# alb32r003x register map
Vendor: ALB; Series: ALB RT SoC
CPU: ALB XF, little endian
Registers are 32-bit, access not given, reset 0x0 unless marked. A register's access mark holds for its fields unless they carry their own. Offsets are from the block's base; [hi:lo] are bit positions.

## LIN1 — LIN1: Local Interconnect Network controller 1 for single-wire automotive serial communication
Base 0x27000000
Same registers: LIN2 0x27001000
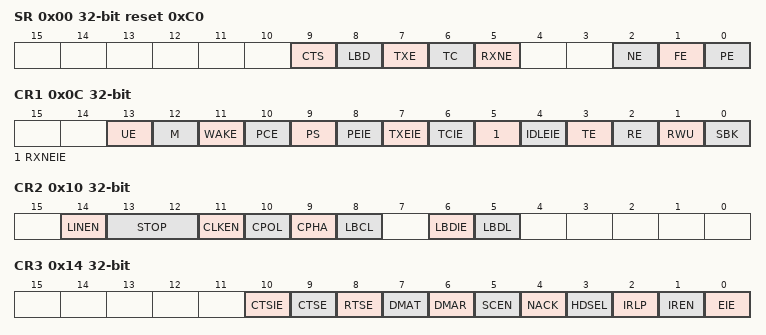
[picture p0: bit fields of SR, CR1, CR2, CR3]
0x00 SR access per field reset 0xC0 — USART status register. Monitors the status of the USART communication interface.
  [9] CTS rw — CTS Flag:This bit is set by hardware when the nCTS input changes state
    0=No change on nCTS status line; 1=Change on nCTS status line
  [8] LBD rw — LIN Break Detection Flag
    0=No LIN break (LIN break not detected); 1=LIN break detected
  [7] TXE ro — Transmit Data Register Empty
    0=Nottransferred (Data not transferred to shift register); 1=Transferred (Data transferred to shift register)
  [6] TC rw — Transmission Complete
    0=Incomplete (Transmission not complete); 1=Complete (Transmission complete)
  [5] RXNE rw — Read Data Register Not Empty
    0=Noreceived (No data received); 1=Received data ready to be read
  [2] NE ro — Noise Error Flag
    0=No noise detected; 1=Noise detected
  [1] FE ro — Framing Error
    0=Noerror (No framing error detected); 1=Error (Framing error or break character detected)
  [0] PE ro — Parity Error
    0=No parity error; 1=Parity error
0x04 DR — USART data register. A bidirectional register for transmitting and receiving data.
0x08 BRR — USART baud rate register. Used to set the baud rate for communication.
0x0C CR1 rw — USART control register 1. Contains the main configuration bits and enable bits.
  [13] UE — USART enable or disabled
    0=Disabled (USART prescaler and output disabled); 1=Enabled (USART module enabled)
  [12] M — Word length:This bit defines the data word length. It is set and cleared by software.
    0=1 Start bit, 8 data bits, n stop bits; 1=1 Start bit, 9 data bits, n stop bits
  [11] WAKE — Wakeup method:This bit determines the USART wakeup method. It is set and cleared by software.
    0=Wake up by idle bus; 1=Wake up by address mark
  [10] PCE — Parity control enable or disable
    0=Disabled (Parity control disabled); 1=Enabled (Parity control enabled)
  [9] PS — Parity selection
    0=Even parity; 1=Odd parity
  [8] PEIE — PE interrupt enable or disable
    0=Disabled (Interrupt generation disabled); 1=Enabled (A USART interrupt is generated when PE=1 in USART_SR)
  [7] TXEIE — TXE interrupt enable or disable
    0=Disabled (Interrupt generation disabled); 1=Enabled (A USART interrupt is generated when TXE=1 in USART_SR)
  [6] TCIE — Transmission complete interrupt enable or disable
    0=Disabled (Interrupt generation disabled); 1=Enabled (A USART interrupt is generated when TC=1 in USART_SR)
  [5] RXNEIE — RXNE interrupt enable or disable
    0=Disabled (Interrupt generation disabled); 1=Enabled (A USART interrupt is generated when ORE=1 or RXNE=1 in USART_SR)
  [4] IDLEIE — IDLE interrupt enable or disbale
    0=Disabled (Interrupt generation disabled); 1=Enabled (A USART interrupt is generated when IDLE=1 in USART_SR)
  [3] TE — Transmitter enable or disbale
    0=Disabled (Transmitter disabled); 1=Enabled (Transmitter enabled)
  [2] RE — Receiver enable or disbale
    0=Disabled (Receiver disabled); 1=Enabled (Receiver enabled, begins searching for start bits on the RX pin)
  [1] RWU — Receiver wakeup:This bit determines whether the USART is put into mute mode.
    0=Operation mode (Receiver in normal operation mode); 1=Mute mode (Receiver in mute mode)
  [0] SBK — Send break:This bit is used to send a break character.
    0=Notbreak (No break character to be sent); 1=Break character will be sent
0x10 CR2 rw — USART control register 2. Configures additional features such as stop bits and clock output.
  [14] LINEN — LIN mode enable or disable
    0=Disabled (LIN mode disabled); 1=Enabled (LIN mode enabled)
  [13:12] STOP — STOP bits:These 2 bits set the number of stop bits.
    0=1 stop bit; 1=0.5 stop bits; 2=2 stop bits; 3=1.5 stop bits
  [11] CLKEN — Clock enable or disable
    0=Disabled (CK pin disabled); 1=Enabled (CK pin enabled)
  [10] CPOL — Clock polarity
    0=low (CK pin remains low during bus idle); 1=high (CK pin remains high during bus idle)
  [9] CPHA — Clock phase
    0=on the second clock edge (Data capture on the first clock edge); 1=on the second clock edge (Data capture on the second clock edge)
  [8] LBCL — Last bit clock pulse
    0=not output (Clock pulse for the last data bit is not output on CK); 1=output (Clock pulse for the last data bit is output on CK)
  [6] LBDIE — LIN break detection interrupt enable or disable
    0=Disabled (Interrupt disabled); 1=Enabled (An interrupt is generated whenever LBD=1 in the USART_SR register.)
  [5] LBDL — LIN break detection length
    0=10-bit break detection; 1=11-bit break detection
0x14 CR3 rw — USART control register 3. Configures advanced features like DMA and hardware flow control.
  [10] CTSIE — CTS interrupt enable or disable
    0=Disabled (Interrupt disabled); 1=Enabled (An interrupt is generated when CTS=1 in the USART_SR register.)
  [9] CTSE — CTS enable or disable
    0=Disabled (CTS hardware flow control disabled); 1=Enabled (CTS mode enabled)
  [8] RTSE — RTS enable or disable
    0=Disabled (RTS hardware flow control disabled); 1=Enabled (RTS mode enabled)
  [7] DMAT — DMA enable transmitter
    0=Disabled (DMA mode for transmission disabled); 1=Enabled (DMA mode for transmission enabled)
  [6] DMAR — DMA enable receiver
    0=Disabled (DMA mode for reception disabled); 1=Enabled (DMA mode for reception enabled)
  [5] SCEN — Smartcard mode enable or disable
    0=Disabled (Smartcard mode disabled); 1=Enabled (Smartcard mode enabled)
  [4] NACK — Half-duplex selection
    0=Notsent (NACK is not sent upon parity error); 1=Sent (NACK is sent upon parity error)
  [3] HDSEL — Half-duplex selection
    0=Notselected (Half-duplex mode not selected); 1=Selected (Half-duplex mode selected)
  [2] IRLP — IrDA low-power
    0=Normal mode; 1=Low-power mode
  [1] IREN — IrDA mode enable or disable
    0=Disabled (IrDA mode disabled); 1=Enabled (IrDA mode enabled)
  [0] EIE — Error interrupt enable or disable
    0=Disabled (Interrupt disabled); 1=Enabled (An interrupt is generated if DMAR=1 in USART_CR3 and (FE=1 or ORE=1 or NE=1 in USART_SR).)
0x18 GTPR rw — USART guard time and prescaler register. Used for specific modes like SmartCard.
  [7:0] PSC[7:0] — Prescaler value- In IrDA low-power mode
    1=Source clock divided by 1; 2=Source clock divided by 2
